# PN74xxAU register map
File version: 2
CPU: CM0 r0p0, little endian, no MPU, no FPU, 2 interrupt priority bits
Registers are 32-bit, read-write, reset 0x0 unless marked. A register's access mark holds for its fields unless they carry their own. Offsets are from the block's base; [hi:lo] are bit positions; {n}, {i} and the like mark numbered series.

## HostIf — Host Interface
Base 0x40020000
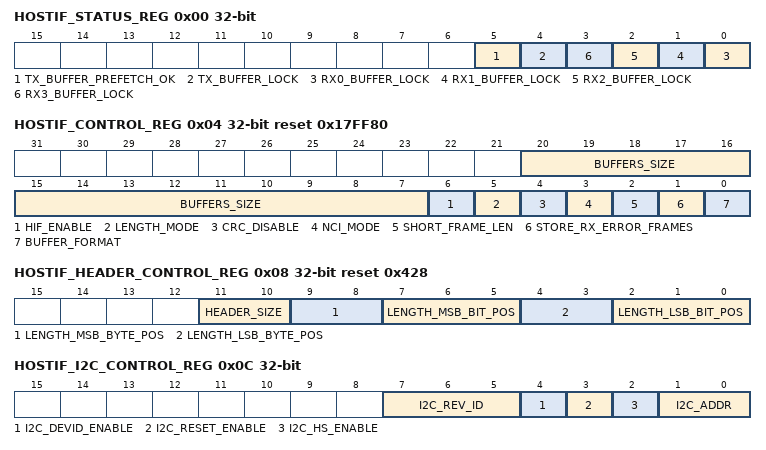
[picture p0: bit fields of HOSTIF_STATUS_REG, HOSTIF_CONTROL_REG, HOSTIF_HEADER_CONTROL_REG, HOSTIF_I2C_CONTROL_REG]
0x00 HOSTIF_STATUS_REG ro — Status
  [5] TX_BUFFER_PREFETCH_OK — 1 - Read prefetch of TX buffer completed
  [4] TX_BUFFER_LOCK — 1 - TX buffer is currently in use by the HW.
  [n] RX{n}_BUFFER_LOCK (n=0..3) — 1 - RX buffer {n} is currently in use by the HW.
0x04 HOSTIF_CONTROL_REG reset 0x17FF80 — Control
  [20:7] BUFFERS_SIZE — RAM aperture size
  [6] HIF_ENABLE — Enables the signal lines MOSI, SCK, NSS, I2C_SDA, I2C_SCL) from the PCR block
  [5] LENGTH_MODE — 0 - Length in mem and in transfered over HDLL header 1 - Length in register. Not transfered in I2C/SPI
  [4] CRC_DISABLE — 0 - CRC active 1 - No CRC
  [3] NCI_MODE — 0 - NCI not used 1 - NCI mode active: CRC_DISABLE and LENGTH_MODE are used
  [2] SHORT_FRAME_LEN — Maximum length of a short frame (in bytes) 0 - 2 bytes 1 - 3 bytes
  [1] STORE_RX_ERROR_FRAMES — 1- Store erroneous RX frames. RX<n>_DATA_READY is set by Host IF as if frame were received error-free
  [0] BUFFER_FORMAT — 0 - HDLL Frames; 1 - Native format
0x08 HOSTIF_HEADER_CONTROL_REG reset 0x428 — Header Control
  [11:10] HEADER_SIZE — Numbers of bytes -1 of the header
  [9:8] LENGTH_MSB_BYTE_POS — Byte position of Length MSB (in recepetion order)
  [7:5] LENGTH_MSB_BIT_POS — Bit position of Length MSB
  [4:3] LENGTH_LSB_BYTE_POS — Byte position of Length LSB (in recepetion order)
  [2:0] LENGTH_LSB_BIT_POS — Bit position of Length LSB
0x0C HOSTIF_I2C_CONTROL_REG — I2C control
  [7:5] I2C_REV_ID — device_id_rev(2:0)
  [4] I2C_DEVID_ENABLE — 1 - Enable Device ID defined in the I2C standard
  [3] I2C_RESET_ENABLE — 1 - Enable Soft Reset sequence defined in the I2C standard
  [2] I2C_HS_ENABLE — 1 - Enable High-speed mode
  [1:0] I2C_ADDR — Set two LSBs of the I2C address
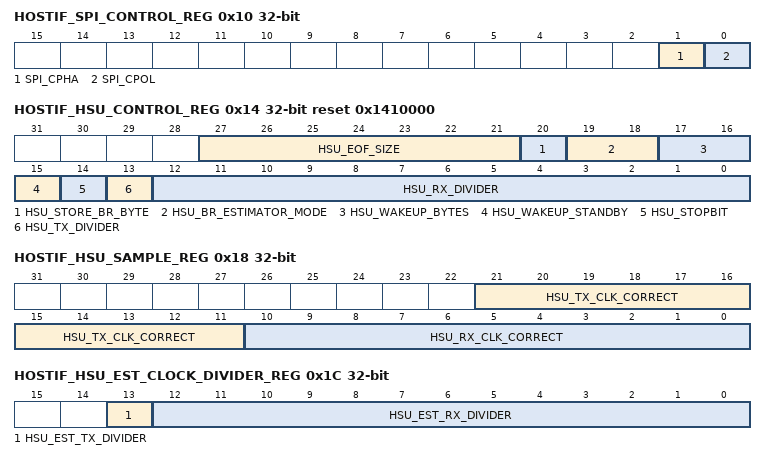
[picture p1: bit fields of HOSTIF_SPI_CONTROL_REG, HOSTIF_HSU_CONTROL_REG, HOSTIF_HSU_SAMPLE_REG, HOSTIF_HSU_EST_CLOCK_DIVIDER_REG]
0x10 HOSTIF_SPI_CONTROL_REG — SPI control
  [1] SPI_CPHA — SPI clock phase
  [0] SPI_CPOL — SPI clock polarity
0x14 HOSTIF_HSU_CONTROL_REG reset 0x1410000 — HSU control Reg
  [27:21] HSU_EOF_SIZE — EOF duration in bit number
  [20] HSU_STORE_BR_BYTE — 1: the first 0 used to estimate baudrate is stored in memory
  [19:18] HSU_BR_ESTIMATOR_MODE — 00: inactive - 01: automatic - 10 active without clock setting
  [17:16] HSU_WAKEUP_BYTES — Number of bytes lost during wakeup at RTS rising edge
  [15] HSU_WAKEUP_STANDBY — 1: simulate reception of bytes loast during wakeup from standby phase (number of bytes specified in HSU_WAKEUP_BYTES).
  [14] HSU_STOPBIT — 0: 1 stopbit- 1: 2 stopbits
  [13] HSU_TX_DIVIDER — 0: Use HSU Rx Divider. 1: Use HSU_RX_DIVIDER+1
  [12:0] HSU_RX_DIVIDER — Clock Divider for Rx sampling
0x18 HOSTIF_HSU_SAMPLE_REG — HSU sample Reg
  [21:11] HSU_TX_CLK_CORRECT — Used to correct Clock division: if TX_CLK_CORRECT[i]=1, then duration of bit i will be extended by 1 clock cycle
  [10:0] HSU_RX_CLK_CORRECT — Used to correct Clock division: if RX_CLK_CORRECT[i]=1, then duration of bit i will be extended by 1 clock cycle
0x1C HOSTIF_HSU_EST_CLOCK_DIVIDER_REG ro — HSU estimated clock dividers
  [13] HSU_EST_TX_DIVIDER — Estimated value for HSU_TX_DIVIDER
  [12:0] HSU_EST_RX_DIVIDER — Estimated value for HSU_RX_DIVIDER
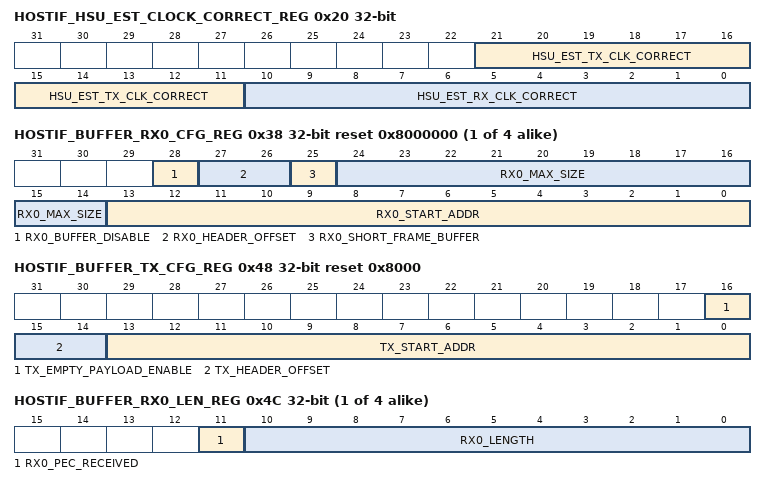
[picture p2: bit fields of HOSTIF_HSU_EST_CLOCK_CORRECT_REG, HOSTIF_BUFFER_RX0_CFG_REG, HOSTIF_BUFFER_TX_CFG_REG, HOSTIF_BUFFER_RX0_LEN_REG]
0x20 HOSTIF_HSU_EST_CLOCK_CORRECT_REG ro — HSU estimated clock correct parameters
  [21:11] HSU_EST_TX_CLK_CORRECT — Estimated value for HSU_TX_CLK_CORRECT
  [10:0] HSU_EST_RX_CLK_CORRECT — Estimated value for HSU_RX_CLK_CORRECT
{0x38+4i} HOSTIF_BUFFER_RX{i}_CFG_REG reset 0x8000000 (i=0..3) — RX buffer {i} configuration
  [28] RX{i}_BUFFER_DISABLE — 1 - buffer is disabled
  [27:26] RX{i}_HEADER_OFFSET — number of padding bytes (MSbyte) which should be added to the first word written to RX buffer in order that the payload is always word-aligned
  [25] RX{i}_SHORT_FRAME_BUFFER — 1 - buffer assigned to short frames 0 - buffer assigned to non-short frames
  [24:14] RX{i}_MAX_SIZE — Maximum size (bytes) of RX buffer {i}
  [13:0] RX{i}_START_ADDR — Start address of RX buffer {i}
0x48 HOSTIF_BUFFER_TX_CFG_REG reset 0x8000 — TX buffer configuration
  [16] TX_EMPTY_PAYLOAD_ENABLE — 1 - only send the first two bytes containing the header from the first word (second word in Native mode) in the TX buffer. Used to send empty payload packets.
  [15:14] TX_HEADER_OFFSET — Number of bytes to skip in first word of frame (second word in Native mode). Used when sending frames directly from the CLIF RX buffer.
  [13:0] TX_START_ADDR — Start address of TX buffer
{0x4C+4i} HOSTIF_BUFFER_RX{i}_LEN_REG ro (i=0..3) — RX{i} length
  [11] RX{i}_PEC_RECEIVED — 1 - Last byte received was a PEC
  [10:0] RX{i}_LENGTH — RX{i} buffer packet length
0x5C HOSTIF_BUFFER_TX_LEN_REG — Configuration of TX length
  [10:0] TX_LENGTH — TX buffer packet length
0x60 HOSTIF_TIC_TIMEOUT_REG — Inter-character timeout
  [15:0] TX_TIMEOUT_VALUE — Inter-character timeout in 5us steps (max delay 200ms). If set to 0, this feature is disabled
0x64 HOSTIF_WATERLEVEL_REG — Waterlevel
  [10:0] WATERLEVEL — Number of bytes received in incoming frame before triggering an interrupt (pre-empting EOR). If set to 0, this feature is disabled.
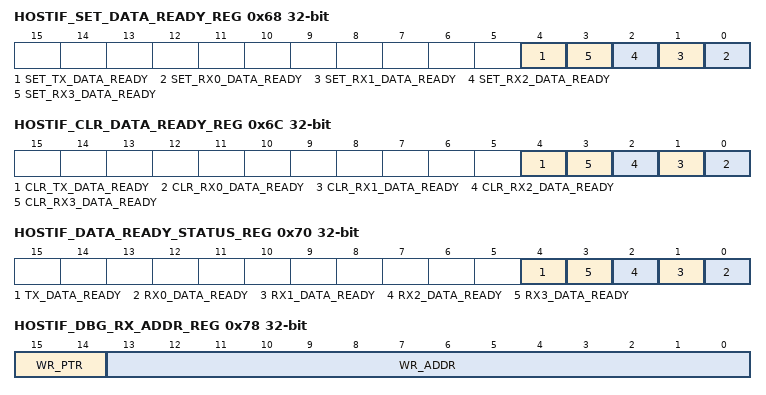
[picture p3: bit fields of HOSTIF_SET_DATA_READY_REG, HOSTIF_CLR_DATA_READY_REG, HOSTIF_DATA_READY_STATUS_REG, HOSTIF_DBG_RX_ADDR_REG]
0x68 HOSTIF_SET_DATA_READY_REG wo — Set buffer ready register
  [4] SET_TX_DATA_READY — Set Tx_data_ready bit
  [n] SET_RX{n}_DATA_READY (n=0..3) — Set Rx{n}_data_ready bit
0x6C HOSTIF_CLR_DATA_READY_REG wo — Clr buffer ready register
  [4] CLR_TX_DATA_READY — Clear Tx_data_ready bit
  [n] CLR_RX{n}_DATA_READY (n=0..3) — Clear Rx{n}_data_ready bit
0x70 HOSTIF_DATA_READY_STATUS_REG ro — Buffer status
  [4] TX_DATA_READY — Frame valid bit for TX buffer. 1 - buffer loaded with frame by FW to be sent to Host 0 - frame successfully sent to Host
  [n] RX{n}_DATA_READY (n=0..3) — Frame valid bit for RX buffer {n}. 1 - buffer contains an error-free frame received from Host 0 - frame has been processed by FW and buffer is free to receive a new frame.
0x74 HOSTIF_DBG_RX_REG ro — Debug received data
  [31:0] RX_REG — Value of received bytes
0x78 HOSTIF_DBG_RX_ADDR_REG ro — Debug received address
  [15:14] WR_PTR — Pointer of next data to write in DBG_RX_REG
  [13:0] WR_ADDR — Next write address
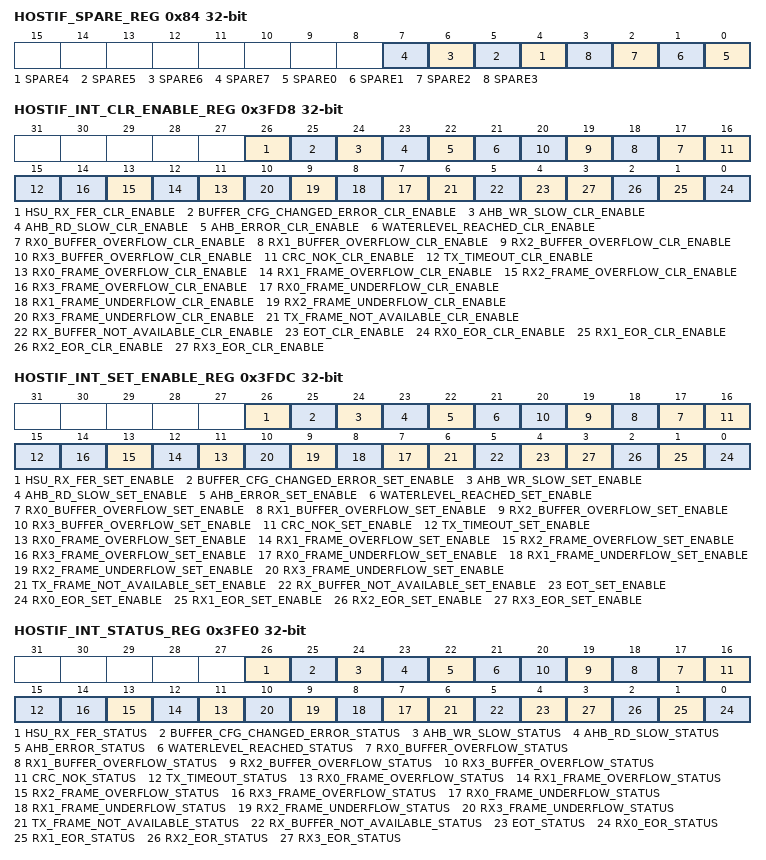
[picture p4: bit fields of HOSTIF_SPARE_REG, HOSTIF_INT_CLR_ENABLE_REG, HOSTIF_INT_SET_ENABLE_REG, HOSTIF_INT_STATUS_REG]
0x84 HOSTIF_SPARE_REG — Spare register
  [n] SPARE{n} (n=4..7) — spare{n} read/write
  [n] SPARE{n} ro (n=0..3) — spare{n} read only
0x3FD8 HOSTIF_INT_CLR_ENABLE_REG wo — Interrupt clear enable register
  [26] HSU_RX_FER_CLR_ENABLE — Clear enable for Rx framing error interrupt
  [25] BUFFER_CFG_CHANGED_ERROR_CLR_ENABLE — Clear enable for buffer_cfg_changed interrupt
  [24] AHB_WR_SLOW_CLR_ENABLE — Clear enable for AHB wr slow interrupt
  [23] AHB_RD_SLOW_CLR_ENABLE — Clear enable for AHB rd slow interrupt
  [22] AHB_ERROR_CLR_ENABLE — Clear enable for AHB error interrupt
  [21] WATERLEVEL_REACHED_CLR_ENABLE — Clear enable for waterlevel reached interrupt 0 - no effect
  [n+17] RX{n}_BUFFER_OVERFLOW_CLR_ENABLE (n=0..3) — Clear enable for max buffer size interrupt for RX buffer in buffer {n}
  [16] CRC_NOK_CLR_ENABLE — Clear enable for data-link Layer CRC error interrupt
  [15] TX_TIMEOUT_CLR_ENABLE — Clear enable for inter-character timeout (TIC) exceeded on transmitted frame interrupt
  [n+11] RX{n}_FRAME_OVERFLOW_CLR_ENABLE (n=0..3) — Clear enable for frame overflow interrupt for RX buffer in buffer {n}
  [n+7] RX{n}_FRAME_UNDERFLOW_CLR_ENABLE (n=0..3) — Clear enable for frame underflow interrupt for RX buffer in {n}
  [6] TX_FRAME_NOT_AVAILABLE_CLR_ENABLE — Clear enable for TX frame not available interrupt
  [5] RX_BUFFER_NOT_AVAILABLE_CLR_ENABLE — Clear enable for no receive buffers available interrupt
  [4] EOT_CLR_ENABLE — Clear enable for EOT interrupt 0
  [n] RX{n}_EOR_CLR_ENABLE (n=0..3) — Clear enable for End of Reception in buffer {n}
0x3FDC HOSTIF_INT_SET_ENABLE_REG wo — Interrupt set enable register
  [26] HSU_RX_FER_SET_ENABLE — Set enable for Rx framing error interrupt
  [25] BUFFER_CFG_CHANGED_ERROR_SET_ENABLE — Set enable for buffer_cfg_changed interrupt
  [24] AHB_WR_SLOW_SET_ENABLE — Set enable for AHB wr slow interrupt
  [23] AHB_RD_SLOW_SET_ENABLE — Set enable for AHB rd slow interrupt
  [22] AHB_ERROR_SET_ENABLE — Set enable for AHB error interrupt
  [21] WATERLEVEL_REACHED_SET_ENABLE — Set enable for waterlevel reached interrupt
  [n+17] RX{n}_BUFFER_OVERFLOW_SET_ENABLE (n=0..3) — Set enable for max buffer size interrupt for RX buffer in buffer {n}
  [16] CRC_NOK_SET_ENABLE — Set enable for data-link Layer CRC error interrupt
  [15] TX_TIMEOUT_SET_ENABLE — Set enable for inter-character timeout (TIC) exceeded on transmitted frame interrupt
  [n+11] RX{n}_FRAME_OVERFLOW_SET_ENABLE (n=0..3) — Set enable for frame overflow interrupt for RX buffer in buffer {n}
  [n+7] RX{n}_FRAME_UNDERFLOW_SET_ENABLE (n=0..3) — Set enable for frame underflow interrupt for RX buffer in buffer {n}
  [6] TX_FRAME_NOT_AVAILABLE_SET_ENABLE — Set enable for TX frame not available interrupt
  [5] RX_BUFFER_NOT_AVAILABLE_SET_ENABLE — Set enable for no receive buffers available interrupt
  [4] EOT_SET_ENABLE — Set enable for EOT interrupt
  [n] RX{n}_EOR_SET_ENABLE (n=0..3) — Set enable for End of Reception in buffer {n}
0x3FE0 HOSTIF_INT_STATUS_REG ro — Interrupt status register
  [26] HSU_RX_FER_STATUS — Rx framing error interrupt
  [25] BUFFER_CFG_CHANGED_ERROR_STATUS — Buffer_cfg_changed interrupt
  [24] AHB_WR_SLOW_STATUS — AHB wr slow interrupt
  [23] AHB_RD_SLOW_STATUS — AHB rd slow interrupt
  [22] AHB_ERROR_STATUS — AHB error interrupt
  [21] WATERLEVEL_REACHED_STATUS — waterlevel reached interrupt status
  [n+17] RX{n}_BUFFER_OVERFLOW_STATUS (n=0..3) — Max buffer size interrupt status for RX buffer in buffer {n}
  [16] CRC_NOK_STATUS — Data-link Layer CRC error interrupt status
  [15] TX_TIMEOUT_STATUS — Inter-character timeout (TIC) exceeded on transmitted frame interrupt status
  [n+11] RX{n}_FRAME_OVERFLOW_STATUS (n=0..3) — Frame overflow interrupt status for RX buffer in buffer {n}
  [n+7] RX{n}_FRAME_UNDERFLOW_STATUS (n=0..3) — Frame underflow interrupt status for RX buffer in buffer {n}
  [6] TX_FRAME_NOT_AVAILABLE_STATUS — TX frame not available interrupt status
  [5] RX_BUFFER_NOT_AVAILABLE_STATUS — No receive buffers available interrupt status
  [4] EOT_STATUS — EOT interrupt status
  [n] RX{n}_EOR_STATUS (n=0..3) — End of Reception in buffer {n} interrupt status
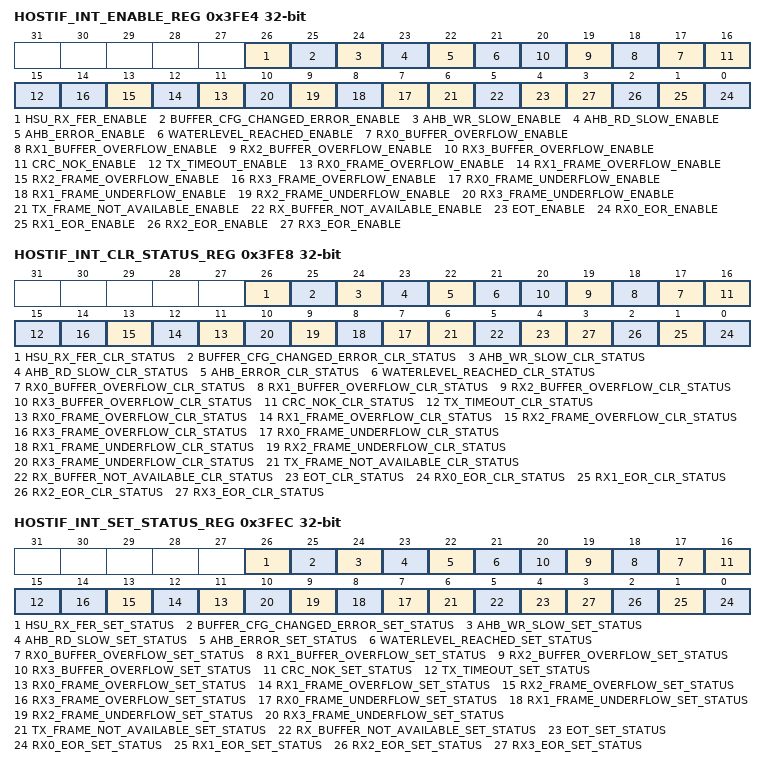
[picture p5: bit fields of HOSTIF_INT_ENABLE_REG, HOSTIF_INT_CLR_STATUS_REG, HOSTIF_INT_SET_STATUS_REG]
0x3FE4 HOSTIF_INT_ENABLE_REG ro — Interrupt enable register
  [26] HSU_RX_FER_ENABLE — Rx framing error interrupt enable
  [25] BUFFER_CFG_CHANGED_ERROR_ENABLE — Buffer_cfg_changed interrupt enable
  [24] AHB_WR_SLOW_ENABLE — AHB wr slow interrupt enable
  [23] AHB_RD_SLOW_ENABLE — AHB rd slow interrupt enable
  [22] AHB_ERROR_ENABLE — AHB error interrupt enable
  [21] WATERLEVEL_REACHED_ENABLE — waterlevel reached interrupt enable
  [n+17] RX{n}_BUFFER_OVERFLOW_ENABLE (n=0..3) — Max buffer size interrupt enable for RX buffer in buffer {n}
  [16] CRC_NOK_ENABLE — Data-link Layer CRC error interrupt enable
  [15] TX_TIMEOUT_ENABLE — Inter-character timeout (TIC) exceeded on transmitted frame interrupt enable
  [n+11] RX{n}_FRAME_OVERFLOW_ENABLE (n=0..3) — Frame overflow interrupt enable for RX buffer in buffer {n}
  [n+7] RX{n}_FRAME_UNDERFLOW_ENABLE (n=0..3) — Frame underflow interrupt enable for RX buffer in buffer {n}
  [6] TX_FRAME_NOT_AVAILABLE_ENABLE — TX frame not available interrupt enable
  [5] RX_BUFFER_NOT_AVAILABLE_ENABLE — No receive buffers available interrupt enable
  [4] EOT_ENABLE — EOT interrupt enable
  [n] RX{n}_EOR_ENABLE (n=0..3) — End of Reception in buffer {n} interrupt enable
0x3FE8 HOSTIF_INT_CLR_STATUS_REG wo — Interrupt clear status register
  [26] HSU_RX_FER_CLR_STATUS — Clear Rx framing error interrupt
  [25] BUFFER_CFG_CHANGED_ERROR_CLR_STATUS — Clear Buffer_cfg_changed interrupt
  [24] AHB_WR_SLOW_CLR_STATUS — Clear AHB wr slow interrupt
  [23] AHB_RD_SLOW_CLR_STATUS — Clear AHB rd slow interrupt
  [22] AHB_ERROR_CLR_STATUS — Clear AHB error interrupt
  [21] WATERLEVEL_REACHED_CLR_STATUS — Clear waterlevel reached interrupt
  [n+17] RX{n}_BUFFER_OVERFLOW_CLR_STATUS (n=0..3) — Clear max buffer size interrupt for RX buffer in buffer {n}
  [16] CRC_NOK_CLR_STATUS — Clear data-link Layer CRC error interrupt
  [15] TX_TIMEOUT_CLR_STATUS — Clear inter-character timeout (TIC) exceeded on transmitted frame interrupt
  [n+11] RX{n}_FRAME_OVERFLOW_CLR_STATUS (n=0..3) — Clear frame overflow interrupt for RX buffer in buffer {n}
  [n+7] RX{n}_FRAME_UNDERFLOW_CLR_STATUS (n=0..3) — Clear frame underflow interrupt for RX buffer in buffer {n}
  [6] TX_FRAME_NOT_AVAILABLE_CLR_STATUS — Clear TX frame not available interrupt
  [5] RX_BUFFER_NOT_AVAILABLE_CLR_STATUS — Clear no receive buffers available interrupt
  [4] EOT_CLR_STATUS — Clear EOT interrupt
  [n] RX{n}_EOR_CLR_STATUS (n=0..3) — Clear End of Reception in buffer {n} interrupt
0x3FEC HOSTIF_INT_SET_STATUS_REG wo — Interrupt set status register
  [26] HSU_RX_FER_SET_STATUS — Set Rx framing error interrupt
  [25] BUFFER_CFG_CHANGED_ERROR_SET_STATUS — Set Buffer_cfg_changed interrupt
  [24] AHB_WR_SLOW_SET_STATUS — Set AHB wr slow interrupt
  [23] AHB_RD_SLOW_SET_STATUS — Set AHB rd slow interrupt
  [22] AHB_ERROR_SET_STATUS — Set AHB error interrupt
  [21] WATERLEVEL_REACHED_SET_STATUS — Set waterlevel reached interrupt
  [n+17] RX{n}_BUFFER_OVERFLOW_SET_STATUS (n=0..3) — Set max buffer size interrupt for RX buffer in buffer {n}
  [16] CRC_NOK_SET_STATUS — Set data-link Layer CRC error interrupt
  [15] TX_TIMEOUT_SET_STATUS — Set inter-character timeout (TIC) exceeded on transmitted frame interrupt
  [n+11] RX{n}_FRAME_OVERFLOW_SET_STATUS (n=0..3) — Set frame overflow interrupt for RX buffer in buffer {n}
  [n+7] RX{n}_FRAME_UNDERFLOW_SET_STATUS (n=0..3) — Set frame underflow interrupt for RX buffer in buffer {n}
  [6] TX_FRAME_NOT_AVAILABLE_SET_STATUS — Set TX frame not available interrupt
  [5] RX_BUFFER_NOT_AVAILABLE_SET_STATUS — Set no receive buffers available interrupt
  [4] EOT_SET_STATUS — Set EOT interrupt
  [n] RX{n}_EOR_SET_STATUS (n=0..3) — Set End of Reception in buffer {n} interrupt
